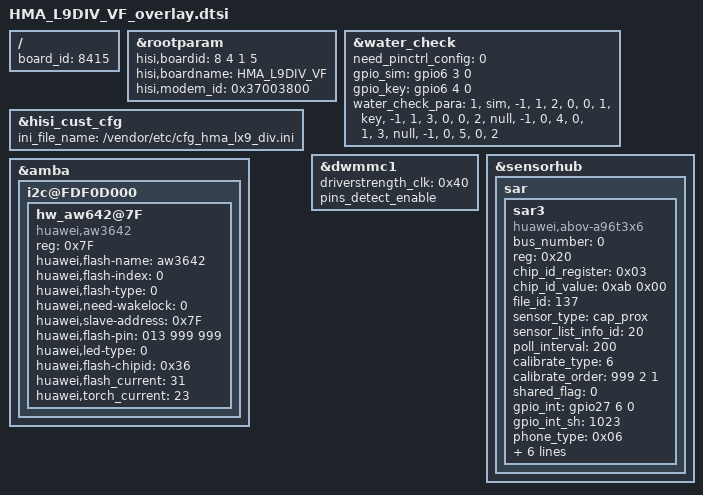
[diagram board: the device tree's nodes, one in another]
/**
 * Copyright (C) 2014 Hisilicon Ltd.
 *
 *  This program is free software; you can redistribute it and/or modify
 *  it under the terms of the GNU General Public License version 2 as
 *  publishhed by the Free Software Foundation.
 */

/include/ "HMA_LX9_VE_overlay.dtsi"

/ {
    board_id = <8415>;
};
	&rootparam{
		hisi,boardid = <8 4 1 5>;
		hisi,boardname = "HMA_L9DIV_VF";
		hisi,modem_id = <0x37003800>;
	};

	&water_check {
		need_pinctrl_config = <0>;
		gpio_sim = <&gpio6 3 0>;
		gpio_key = <&gpio6 4 0>;
		/*check_type, gpio_name, irq_no, multiple_handle, dmd_offset, prompt, action*/
		water_check_para =
				"1","sim","-1","1","2","0","0",
				"1","key","-1","1","3","0","0",
				"2","null","-1","0","4","0","1",
				"3","null","-1","0","5","0","2";
		status = "ok";
	};

	/*hisi customize*/
	&hisi_cust_cfg {
		ini_file_name = "/vendor/etc/cfg_hma_lx9_div.ini";
	};


	&dwmmc1 {
		/*14MA_1 for sd clk*/
		driverstrength_clk = <0x40>;
		/* enable nmcard 4pins detect */
		pins_detect_enable;
	};

	&amba {
		i2c@FDF0D000 {
			hw_aw642@7F{
				compatible = "huawei,aw3642";
				reg = <0x7F>;
				huawei,flash-name = "aw3642";
				huawei,flash-index = <0>;
				huawei,flash-type = <0>;
				huawei,need-wakelock = <0>;
				huawei,slave-address = <0x7F>;
				huawei,flash-pin = <013 999 999>;
				huawei,led-type = <0>; /* 1, dual tempature; 0, dual white */
				huawei,flash-chipid = <0x36>;
				huawei,flash_current = <31>;
				huawei,torch_current = <23>;
				status = "ok";
			};
		};
	};
    &sensorhub{
		sar{
			sar3 {
				compatible="huawei,abov-a96t3x6";
				bus_number=<0>;
				reg=<0x20>;
				chip_id_register=<0x03>;
				chip_id_value=<0xab 0x00>;
				file_id=<137>;
				sensor_type="cap_prox";
				sensor_list_info_id=<20>;
				poll_interval=<200>;
				calibrate_type=<6>; // bit config 101(b) adapt to the param calibrate calibrate order
				calibrate_order = "999 2 1"; // 0:free  1:near  2:far  3:other
				shared_flag=<0>;
				gpio_int=<&gpio27 6 0>;
				gpio_int_sh=<1023>;
				status = "ok";
				phone_type = /bits/ 16 <0x06>; // 6:HMA 7:LAYA
				to_modem_threshold = /bits/ 16 <0xc8 0x00 0x00 0x00 0x00 0x00 0x00 0x00>;
				ph = <0x5>;
				calibrate_thred = /bits/ 16 <0 0 0 0>; // for the factory far and near calibrate
				sensorlist_name="CAP_PROX sensor-a96t3x6";
				vendor="abov";
			};
		  };
	};
